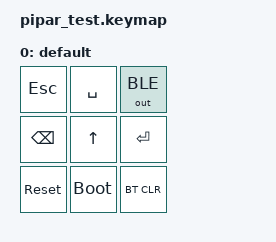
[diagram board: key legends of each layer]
/*
 * Copyright (c) 2022 The ZMK Contributors
 *
 * SPDX-License-Identifier: MIT
 */

#include <behaviors.dtsi>
#include <dt-bindings/zmk/keys.h>
#include <dt-bindings/zmk/bt.h>
#include <dt-bindings/zmk/outputs.h>

#define BASE        0

/ {
  
  sensors: sensors {
    compatible = "zmk,sensors";
  };

  keymap {
    compatible = "zmk,keymap";

    default_layer {
        display-name = "default";
        bindings = <
            &kp ESC  &kp SPACE  &out OUT_BLE
            &kp BSPC &kp UP     &kp ENTER
            &sys_reset  &bootloader &bt BT_CLR
        >;

    };
  };
};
